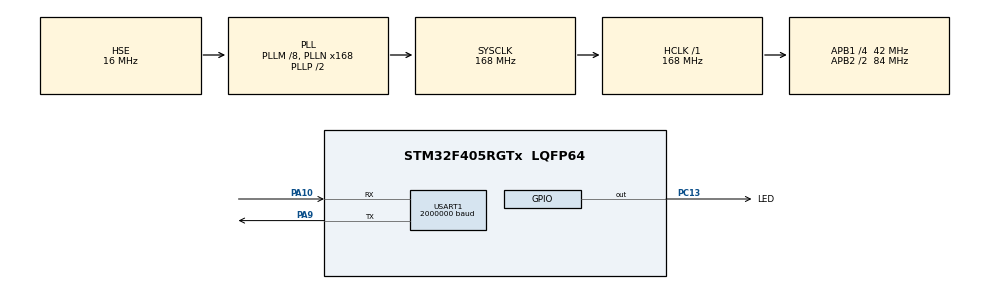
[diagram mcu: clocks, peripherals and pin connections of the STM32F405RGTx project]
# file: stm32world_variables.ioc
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Mcu.Family=STM32F4
Mcu.Name=STM32F405RGTx
Mcu.Package=LQFP64
NVIC.PriorityGroup=NVIC_PRIORITYGROUP_4
PA10.Mode=Asynchronous
PA10.Signal=USART1_RX
PA13.Mode=Trace_Asynchronous_SW
PA13.Signal=SYS_JTMS-SWDIO
PA14.Mode=Trace_Asynchronous_SW
PA14.Signal=SYS_JTCK-SWCLK
PA9.Mode=Asynchronous
PA9.Signal=USART1_TX
PB3.Mode=Trace_Asynchronous_SW
PB3.Signal=SYS_JTDO-SWO
PC13-ANTI_TAMP.GPIO_Label=LED
PC13-ANTI_TAMP.GPIO_ModeDefaultOutputPP=GPIO_MODE_OUTPUT_OD
PC13-ANTI_TAMP.GPIO_PuPd=GPIO_NOPULL
PC13-ANTI_TAMP.PinState=GPIO_PIN_SET
PC13-ANTI_TAMP.Signal=GPIO_Output
PH0-OSC_IN.Mode=HSE-External-Oscillator
PH0-OSC_IN.Signal=RCC_OSC_IN
PH1-OSC_OUT.Mode=HSE-External-Oscillator
PH1-OSC_OUT.Signal=RCC_OSC_OUT
ProjectManager.HeapSize=0x200
ProjectManager.StackSize=0x400
ProjectManager.TargetToolchain=STM32CubeIDE
RCC.48MHZClocksFreq_Value=84000000
RCC.AHBFreq_Value=168000000
RCC.APB1CLKDivider=RCC_HCLK_DIV4
RCC.APB1Freq_Value=42000000
RCC.APB1TimFreq_Value=84000000
RCC.APB2CLKDivider=RCC_HCLK_DIV2
RCC.APB2Freq_Value=84000000
RCC.APB2TimFreq_Value=168000000
RCC.CortexFreq_Value=168000000
RCC.HCLKFreq_Value=168000000
RCC.HSE_VALUE=16000000
RCC.HSI_VALUE=16000000
RCC.LSE_VALUE=32768
RCC.PLLM=8
RCC.PLLN=168
RCC.PLLSourceVirtual=RCC_PLLSOURCE_HSE
RCC.SYSCLKFreq_VALUE=168000000
RCC.SYSCLKSource=RCC_SYSCLKSOURCE_PLLCLK
RCC.VCOOutputFreq_Value=336000000
USART1.BaudRate=2000000
USART1.VirtualMode=VM_ASYNC
board=custom

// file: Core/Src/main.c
/* USER CODE BEGIN Header */
/**
 ******************************************************************************
 * @file           : main.c
 * @brief          : Main program body
 ******************************************************************************
 * @attention
 *
 * Copyright (c) 2024 Lars Boegild Thomsen <lth@stm32world.com>
 * All rights reserved.
 *
 * This software is licensed under terms that can be found in the LICENSE file
 * in the root directory of this software component.
 * If no LICENSE file comes with this software, it is provided AS-IS.
 *
 ******************************************************************************
 */
/* USER CODE END Header */
#include "main.h"

/* USER CODE BEGIN Includes */
#include <stdlib.h>
#include <stdio.h>
#include <string.h>
/* USER CODE END Includes */

/* USER CODE BEGIN PTD */

typedef struct {
    int a;
    int b;
    int c;
} s_struct;

/* USER CODE END PTD */

UART_HandleTypeDef huart1;

void SystemClock_Config(void);
static void MX_GPIO_Init(void);
static void MX_USART1_UART_Init(void);

/* USER CODE BEGIN 0 */

// Send printf to uart1
__attribute__((section(".ccmram"))) int _write(int fd, char *ptr, int len) {
    HAL_StatusTypeDef hstatus;

    if (fd == 1 || fd == 2) {
        hstatus = HAL_UART_Transmit(&huart1, (uint8_t*) ptr, len, HAL_MAX_DELAY);
        if (hstatus == HAL_OK)
            return len;
        else
            return -1;
    }
    return -1;
}

void inc1(int v) { // v is passed by value, so this will NOT work
    ++v;
}

int inc2(int v) { // v is passed by value - returns inc
    return ++v;
}

void inc3(int *v) { // v is passed by reference
    ++*v;
}

void sum1(s_struct s) {
    s.c = s.a + s.b;
}

s_struct sum2(s_struct s) {
    s.c = s.a + s.b;
    return s;
}

void sum3(s_struct *s) {
    s->c = s->a + s->b;
}

/* USER CODE END 0 */

int main(void)
{

    /* MCU Configuration--------------------------------------------------------*/

    /* Reset of all peripherals, Initializes the Flash interface and the Systick. */
    HAL_Init();

    /* Configure the system clock */
    SystemClock_Config();

    /* Initialize all configured peripherals */
    MX_GPIO_Init();
    MX_USART1_UART_Init();
    /* USER CODE BEGIN 2 */

    printf("\n\n\n--------\nStarting\n");

    int i = 10;
    printf("before inc1: %d\n", i);
    inc1(i);
    printf("after inc1: %d\n", i);

    //int x = inc2(i);
    i = inc2(i);
    printf("after inc2: %d\n", i);

    inc3(&i);
    printf("after inc3: %d\n", i);

    int *ip;
    ip = &i;
    *ip = 20;
    inc3(ip);
    printf("after inc3: %d\n", i);

    s_struct s = { 10, 10, 0 };
    printf("before sum1: a = %d b = %d c = %d\n", s.a, s.b, s.c);
    sum1(s);
    printf("after sum1: a = %d b = %d c = %d\n", s.a, s.b, s.c);

    s = sum2(s);
    printf("after sum2: a = %d b = %d c = %d\n", s.a, s.b, s.c);

    s.c = 0;
    printf("before sum3: a = %d b = %d c = %d\n", s.a, s.b, s.c);
    sum3(&s);
    printf("after sum3: a = %d b = %d c = %d\n", s.a, s.b, s.c);

    uint8_t a[] = {
            1,
            2,
            3,
            4,
            5
    };

    for (int n = 0; n < sizeof(a) / sizeof(a[0]); ++n) {
        printf("a[%d] = %d\n", n, a[n]);
    }

    //uint8_t *ap = &a[0];
    uint8_t *ap = a;

    for (int n = 0; n < sizeof(a) / sizeof(a[0]); ++n) {
        printf("a[%d] = %d\n", n, ap[n]); // indexing a pointer automatically dereference it
    }

    for (int n = 0; n < sizeof(a) / sizeof(a[0]); ++n) { // deliberately goes outside the size of the array - c will not complain
        printf("a[%d] = %d\n", n, *ap); // printf expect value - pointer need to be dereferenced
        //++ap;
        ap += 1; // Or could be ++ap
    }

    char sbuf[128] = { 0 };

    printf("Length of sbuf = %d\n", sizeof(sbuf));

    char cstr1[] = "This is";
    char cstr2[] = "a string";

    printf("cstr1 len = %d: %s\n", strlen(cstr1), cstr1);
    printf("cstr2 len = %d: %s\n", strlen(cstr2), cstr2);

//    strcpy(sbuf, cstr1);
//    strcat(sbuf, " ");
//    strcat(sbuf, cstr2);

    strncpy(sbuf, cstr1, sizeof(sbuf) - strlen(sbuf) - 1);
    strncat(sbuf, " ", sizeof(sbuf) - strlen(sbuf) - 1);
    strncat(sbuf, cstr2, sizeof(sbuf) - strlen(sbuf) - 1);

    printf("sbuf = %s\n", sbuf);

    char *sbuf2;

    sbuf2 = malloc(128);

    if (sbuf2) {

        strcpy(sbuf2, sbuf);

        printf("sbuf2 len = %d: %s\n", strlen(sbuf2), sbuf2);

        free(sbuf2);
    }

    char cstr3[] = "a string";

    if (strcmp(cstr1, cstr3))
        printf("cstr1 does not match cstr3\n");

    if (strcmp(cstr2, cstr3))
        printf("cstr2 does not match cstr3\n");

    char *loc = strstr(sbuf, "a s");
    printf("location = %d: %s\n", loc - sbuf, loc);

    // Let's play a bit with the heap
    char *sa[5];
    for (int i = 0; i < 5; ++i) {
        sa[i] = malloc(128);
        sprintf(sa[i], "String %d", i);
        printf("%s\n", sa[i]);
    }

    /* USER CODE END 2 */

    /* Infinite loop */
    while (1)
    {

    }
}

void SystemClock_Config(void)
{
    RCC_OscInitTypeDef RCC_OscInitStruct = { 0 };
    RCC_ClkInitTypeDef RCC_ClkInitStruct = { 0 };

    /** Configure the main internal regulator output voltage
     */
    __HAL_RCC_PWR_CLK_ENABLE();
    __HAL_PWR_VOLTAGESCALING_CONFIG(PWR_REGULATOR_VOLTAGE_SCALE1);

    /** Initializes the RCC Oscillators according to the specified parameters
     * in the RCC_OscInitTypeDef structure.
     */
    RCC_OscInitStruct.OscillatorType = RCC_OSCILLATORTYPE_HSE;
    RCC_OscInitStruct.HSEState = RCC_HSE_ON;
    RCC_OscInitStruct.PLL.PLLState = RCC_PLL_ON;
    RCC_OscInitStruct.PLL.PLLSource = RCC_PLLSOURCE_HSE;
    RCC_OscInitStruct.PLL.PLLM = 8;
    RCC_OscInitStruct.PLL.PLLN = 168;
    RCC_OscInitStruct.PLL.PLLP = RCC_PLLP_DIV2;
    RCC_OscInitStruct.PLL.PLLQ = 4;
    if (HAL_RCC_OscConfig(&RCC_OscInitStruct) != HAL_OK)
            {
        Error_Handler();
    }

    /** Initializes the CPU, AHB and APB buses clocks
     */
    RCC_ClkInitStruct.ClockType = RCC_CLOCKTYPE_HCLK | RCC_CLOCKTYPE_SYSCLK
            | RCC_CLOCKTYPE_PCLK1 | RCC_CLOCKTYPE_PCLK2;
    RCC_ClkInitStruct.SYSCLKSource = RCC_SYSCLKSOURCE_PLLCLK;
    RCC_ClkInitStruct.AHBCLKDivider = RCC_SYSCLK_DIV1;
    RCC_ClkInitStruct.APB1CLKDivider = RCC_HCLK_DIV4;
    RCC_ClkInitStruct.APB2CLKDivider = RCC_HCLK_DIV2;

    if (HAL_RCC_ClockConfig(&RCC_ClkInitStruct, FLASH_LATENCY_5) != HAL_OK)
            {
        Error_Handler();
    }
}

static void MX_USART1_UART_Init(void)
{

    huart1.Instance = USART1;
    huart1.Init.BaudRate = 2000000;
    huart1.Init.WordLength = UART_WORDLENGTH_8B;
    huart1.Init.StopBits = UART_STOPBITS_1;
    huart1.Init.Parity = UART_PARITY_NONE;
    huart1.Init.Mode = UART_MODE_TX_RX;
    huart1.Init.HwFlowCtl = UART_HWCONTROL_NONE;
    huart1.Init.OverSampling = UART_OVERSAMPLING_16;
    if (HAL_UART_Init(&huart1) != HAL_OK)
            {
        Error_Handler();
    }

}

static void MX_GPIO_Init(void)
{
    GPIO_InitTypeDef GPIO_InitStruct = { 0 };

    /* GPIO Ports Clock Enable */
    __HAL_RCC_GPIOC_CLK_ENABLE();
    __HAL_RCC_GPIOH_CLK_ENABLE();
    __HAL_RCC_GPIOA_CLK_ENABLE();
    __HAL_RCC_GPIOB_CLK_ENABLE();

    /*Configure GPIO pin Output Level */
    HAL_GPIO_WritePin(LED_GPIO_Port, LED_Pin, GPIO_PIN_SET);

    /*Configure GPIO pin : LED_Pin */
    GPIO_InitStruct.Pin = LED_Pin;
    GPIO_InitStruct.Mode = GPIO_MODE_OUTPUT_OD;
    GPIO_InitStruct.Pull = GPIO_NOPULL;
    GPIO_InitStruct.Speed = GPIO_SPEED_FREQ_LOW;
    HAL_GPIO_Init(LED_GPIO_Port, &GPIO_InitStruct);

}

void Error_Handler(void)
{
    __disable_irq();
    while (1)
    {
    }
}
